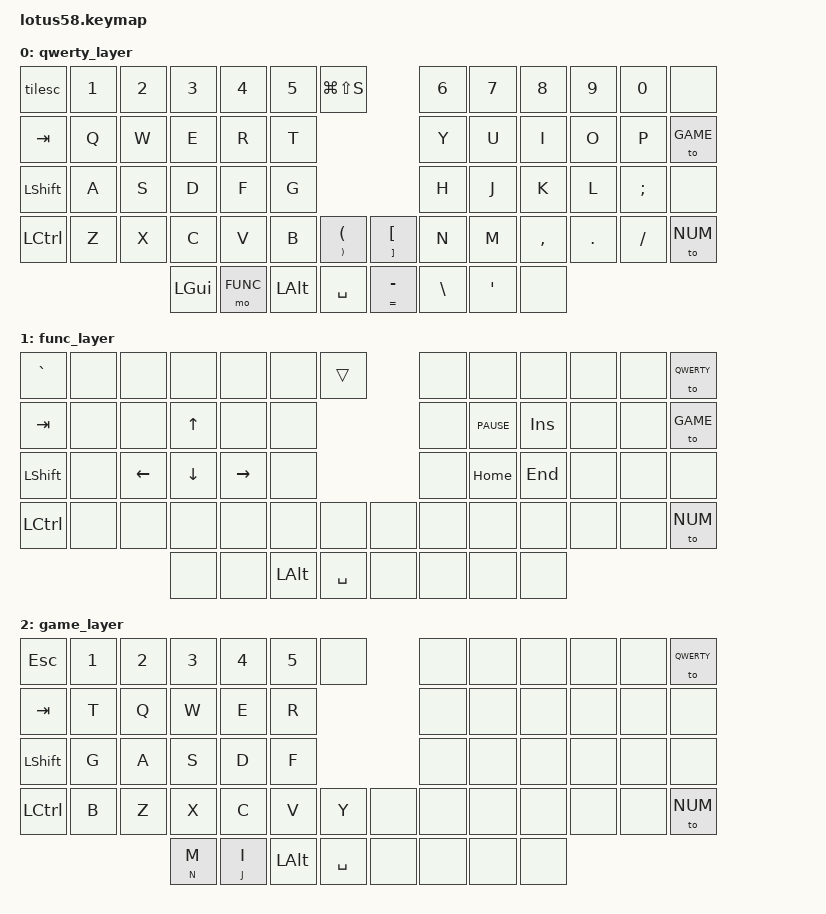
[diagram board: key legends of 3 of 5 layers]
/*
 * Copyright (c) 2020 The ZMK Contributors
 *
 * SPDX-License-Identifier: MIT
 */

#include <behaviors.dtsi>
#include <dt-bindings/zmk/keys.h>
#include <dt-bindings/zmk/bt.h>
#include <dt-bindings/zmk/ext_power.h>

#define ___ &none
#define QWERTY 0
#define FUNC 1
#define GAME 2
#define NUM 3
#define PAUSE PAUSE_BREAK
#define MULTIPLY KP_MULTIPLY

&kscan0 {
    debounce-period = <20>;
};

&sk {
	release-after-ms = <200>;
};

&mt {
	tapping-term-ms = <100>;
};

/ {
	behaviors {
		tilesc: mod_morph_tilde_escape {
			compatible = "zmk,behavior-mod-morph";
			label = "TILDE_ESCAPE";
			#binding-cells = <0>;
			bindings = <&kp ESC>, <&kp TILDE>;
			mods = <(MOD_LSFT)>;
		};

		tlt: behavior_toLayer_tap {
            compatible = "zmk,behavior-hold-tap";
            label = "sticky_tap";
            #binding-cells = <2>;
            flavor = "tap-preferred";
            tapping-term-ms = <200>;
            bindings = <&to>, <&kp>;
        };

		tglt: behavior_togLayer_tap {
            compatible = "zmk,behavior-hold-tap";
            label = "toggle_tap";
            #binding-cells = <2>;
            flavor = "tap-preferred";
            tapping-term-ms = <200>;
            bindings = <&tog>, <&kp>;
        };

	};

	combos {
		compatible = "zmk,combos";

        combo_f1 {
            timeout-ms = <25>;
            key-positions = <0 1>;
            bindings = <&kp F1>;
        };

		combo_f2 {
            timeout-ms = <25>;
            key-positions = <1 2>;
            bindings = <&kp F2>;
        };

		combo_f3 {
            timeout-ms = <25>;
            key-positions = <2 3>;
            bindings = <&kp F3>;
        };

		combo_f4 {
            timeout-ms = <25>;
            key-positions = <3 4>;
            bindings = <&kp F4>;
        };

		combo_f5 {
            timeout-ms = <25>;
            key-positions = <4 5>;
            bindings = <&kp F5>;
        };

		combo_f6 {
            timeout-ms = <25>;
            key-positions = <7 8>;
            bindings = <&kp F6>;
        };

		combo_f7 {
            timeout-ms = <25>;
            key-positions = <8 9>;
            bindings = <&kp F7>;
        };

		combo_f8 {
            timeout-ms = <25>;
            key-positions = <9 10>;
            bindings = <&kp F8>;
        };

		combo_f9 {
            timeout-ms = <25>;
            key-positions = <10 11>;
            bindings = <&kp F9>;
        };

		combo_f10 {
            timeout-ms = <25>;
            key-positions = <11 12>;
            bindings = <&kp F10>;
        };

		combo_f11 {
            timeout-ms = <25>;
            key-positions = <0 2>;
            bindings = <&kp F11>;
        };

		combo_f12 {
            timeout-ms = <25>;
            key-positions = <0 3>;
            bindings = <&kp F12>;
        };

        combo_ret {
            timeout-ms = <50>;
            key-positions = <43 54>;
            bindings = <&kp RET>;
        };
        
        combo_bspc {
            timeout-ms = <25>;
            key-positions = <16 17>;
            bindings = <&kp BSPC>;
        };

        combo_del {
            timeout-ms = <25>;
            key-positions = <15 16 17>;
            bindings = <&kp DEL>;
        };
	};

	keymap {
		compatible = "zmk,keymap";

		qwerty_layer {
			bindings = <
/*    ╭─────────────┬─────────────┬─────────────┬─────────────┬─────────────┬─────────────┬─────────────╮   ╭─────────────┬─────────────┬─────────────┬─────────────┬─────────────┬─────────────┬─────────────╮ */
       &tilesc       &kp N1        &kp N2        &kp N3        &kp N4        &kp N5        &kp LG(LS(S))                   &kp N6        &kp N7        &kp N8		 &kp N9  	   &kp N0   	 ___
/*    ├─────────────┼─────────────┼─────────────┼─────────────┼─────────────┼─────────────┼─────────────╯   ╰─────────────┼─────────────┼─────────────┼─────────────┼─────────────┼─────────────┼─────────────┤ */
       &kp TAB	     &kp Q  	   &kp W  	     &kp E    	   &kp R		 &kp T                     					   &kp Y         &kp U		   &kp I   	     &kp O   	   &kp P    	 &to GAME
/*    ├─────────────┼─────────────┼─────────────┼─────────────┼─────────────┼─────────────┤                               ├─────────────┼─────────────┼─────────────┼─────────────┼─────────────┼─────────────┤ */
       &kp LSHFT	 &kp A  	   &kp S 	     &kp D    	   &kp F    	 &kp G                      				   &kp H	     &kp J		   &kp K   	     &kp L   	   &kp SEMI 	 ___
/*    ├─────────────┼─────────────┼─────────────┼─────────────┼─────────────┼─────────────┼─────────────╮   ╭─────────────┼─────────────┼─────────────┼─────────────┼─────────────┼─────────────┼─────────────┤ */
       &kp LCTRL 	 &kp Z  	   &kp X  	     &kp C    	   &kp V		 &kp B		   &mt RPAR LPAR     &mt RBKT LBKT &kp N	     &kp M		   &kp COMMA 	 &kp DOT 	   &kp FSLH 	 &to NUM
/*    ╰─────────────┴─────────────┴─────────────┼─────────────┼─────────────┼─────────────┼─────────────┤   ├─────────────┼─────────────┼─────────────┴─────────────┴─────────────┴─────────────┴─────────────╯ */
                                                 &kp LGUI 	   &mo FUNC 	 &kp LALT  	   &kp SPACE  		 &mt EQUAL MINUS &kp BSLH     &kp SQT    	___
/*                                              ╰─────────────┴─────────────┴─────────────┴─────────────╯   ╰─────────────┴─────────────┴─────────────┴─────────────╯                                           */
			>;

			sensor-bindings = <&inc_dec_kp PG_UP PG_DN>;
		};

		func_layer {
			bindings = <
/*    ╭─────────────┬─────────────┬─────────────┬─────────────┬─────────────┬─────────────┬─────────────╮   ╭─────────────┬─────────────┬─────────────┬─────────────┬─────────────┬─────────────┬─────────────╮ */
       &kp GRAVE     ___	       ___		     ___		   ___           ___		   &trans		                   ___           ___           ___           ___           ___           &to QWERTY
/*    ├─────────────┼─────────────┼─────────────┼─────────────┼─────────────┼─────────────┼─────────────╯   ╰─────────────┼─────────────┼─────────────┼─────────────┼─────────────┼─────────────┼─────────────┤ */
       &kp TAB	     ___           ___		     &kp UP		   ___	         ___							               ___           &kp PAUSE     &kp INS	     ___           ___	         &to GAME
/*    ├─────────────┼─────────────┼─────────────┼─────────────┼─────────────┼─────────────┤                               ├─────────────┼─────────────┼─────────────┼─────────────┼─────────────┼─────────────┤ */
       &kp LSHFT	 ___           &kp LEFT	     &kp DOWN	   &kp RIGHT     ___							               ___      	 &kp HOME      &kp END	     ___	       ___	         ___
/*    ├─────────────┼─────────────┼─────────────┼─────────────┼─────────────┼─────────────┼─────────────╮   ╭─────────────┼─────────────┼─────────────┼─────────────┼─────────────┼─────────────┼─────────────┤ */
       &kp LCTRL     ___	       ___		     ___           ___           ___    	   ___		         ___           ___           ___   	       ___           ___           ___       	 &to NUM
/*    ╰─────────────┴─────────────┴─────────────┼─────────────┼─────────────┼─────────────┼─────────────┤   ├─────────────┼─────────────┼─────────────┴─────────────┴─────────────┴─────────────┴─────────────╯ */
                                                 ___           ___	         &kp LALT      &kp SPACE	     ___	       ___	         ___	       ___
/*                                              ╰─────────────┴─────────────┴─────────────┴─────────────╯   ╰─────────────┴─────────────┴─────────────┴─────────────╯                                           */
			>;

			sensor-bindings = <&inc_dec_kp C_VOL_UP C_VOL_DN>;
		};

		game_layer {
			bindings = <
/*    ╭─────────────┬─────────────┬─────────────┬─────────────┬─────────────┬─────────────┬─────────────╮   ╭─────────────┬─────────────┬─────────────┬─────────────┬─────────────┬─────────────┬─────────────╮ */
       &kp ESC		 &kp N1	       &kp N2	     &kp N3        &kp N4        &kp N5   	   ___        	                   ___           ___           ___           ___           ___           &to QWERTY
/*    ├─────────────┼─────────────┼─────────────┼─────────────┼─────────────┼─────────────┼─────────────╯   ╰─────────────┼─────────────┼─────────────┼─────────────┼─────────────┼─────────────┼─────────────┤ */
       &kp TAB		 &kp T         &kp Q 	     &kp W         &kp E         &kp R                 	                       ___           ___           ___           ___           ___           ___
/*    ├─────────────┼─────────────┼─────────────┼─────────────┼─────────────┼─────────────┤                               ├─────────────┼─────────────┼─────────────┼─────────────┼─────────────┼─────────────┤ */
       &kp LSHFT	 &kp G	       &kp A  	     &kp S         &kp D         &kp F                 	                       ___           ___           ___           ___           ___           ___
/*    ├─────────────┼─────────────┼─────────────┼─────────────┼─────────────┼─────────────┼─────────────╮   ╭─────────────┼─────────────┼─────────────┼─────────────┼─────────────┼─────────────┼─────────────┤ */
       &kp LCTRL 	 &kp B	       &kp Z  	     &kp X         &kp C         &kp V    	   &kp Y   	         ___           ___           ___           ___           ___           ___           &to NUM
/*    ╰─────────────┴─────────────┴─────────────┼─────────────┼─────────────┼─────────────┼─────────────┤   ├─────────────┼─────────────┼─────────────┴─────────────┴─────────────┴─────────────┴─────────────╯ */
                     		                     &mt N M       &mt J I       &kp LALT      &kp SPACE	     ___           ___           ___           ___
/*                                              ╰─────────────┴─────────────┴─────────────┴─────────────╯   ╰─────────────┴─────────────┴─────────────┴─────────────╯                                           */
			>;

			sensor-bindings = <&inc_dec_kp PG_UP PG_DN>;
		};

		number_layer {
			bindings = <
/*    ╭─────────────┬─────────────┬─────────────┬─────────────┬─────────────┬─────────────┬─────────────╮   ╭─────────────┬─────────────┬─────────────┬─────────────┬─────────────┬─────────────┬─────────────╮ */
       ___           ___           ___           ___           ___           ___           ___               ___           ___           &kp KP_NLCK   &kp KP_SLASH  &kp MULTIPLY  &kp KP_MINUS  &to QWERTY
/*    ├─────────────┼─────────────┼─────────────┼─────────────┼─────────────┼─────────────┼─────────────╯   ╰─────────────┼─────────────┼─────────────┼─────────────┼─────────────┼─────────────┼─────────────┤ */
       ___           ___           ___           ___           ___           ___                                           ___           &kp KP_N7     &kp KP_N8     &kp KP_N9     &kp KP_PLUS   &to GAME
/*    ├─────────────┼─────────────┼─────────────┼─────────────┼─────────────┼─────────────┤                               ├─────────────┼─────────────┼─────────────┼─────────────┼─────────────┼─────────────┤ */
       ___           ___           ___           ___           ___           ___                                           ___           &kp KP_N4     &kp KP_N5     &kp KP_N6     ___           ___
/*    ├─────────────┼─────────────┼─────────────┼─────────────┼─────────────┼─────────────┼─────────────╮   ╭─────────────┼─────────────┼─────────────┼─────────────┼─────────────┼─────────────┼─────────────┤ */
       ___           ___           ___           ___           ___           ___           ___               ___           ___           &kp KP_N1     &kp KP_N2     &kp KP_N3     ___           ___
/*    ╰─────────────┴─────────────┴─────────────┼─────────────┼─────────────┼─────────────┼─────────────┤   ├─────────────┼─────────────┼─────────────┴─────────────┴─────────────┴─────────────┴─────────────╯ */
                     		                     ___           ___           ___           ___               &kp KP_ENTER  &kp N0        &kp DOT       ___
/*                                              ╰─────────────┴─────────────┴─────────────┴─────────────╯   ╰─────────────┴─────────────┴─────────────┴─────────────╯                                           */
			>;

			sensor-bindings = <&inc_dec_kp C_VOL_UP C_VOL_DN>;
		};

		blank_layer {
			bindings = <
/*    ╭─────────────┬─────────────┬─────────────┬─────────────┬─────────────┬─────────────┬─────────────╮   ╭─────────────┬─────────────┬─────────────┬─────────────┬─────────────┬─────────────┬─────────────╮ */
       ___           ___           ___           ___           ___           ___           ___               ___           ___           ___           ___           ___           ___           &to QWERTY
/*    ├─────────────┼─────────────┼─────────────┼─────────────┼─────────────┼─────────────┼─────────────╯   ╰─────────────┼─────────────┼─────────────┼─────────────┼─────────────┼─────────────┼─────────────┤ */
       ___           &kp Q         ___           ___           ___           ___                                           ___           ___           ___           ___           ___           ___
/*    ├─────────────┼─────────────┼─────────────┼─────────────┼─────────────┼─────────────┤                               ├─────────────┼─────────────┼─────────────┼─────────────┼─────────────┼─────────────┤ */
       ___           ___           ___           ___           ___           ___                                           ___           ___           ___           ___           ___           ___
/*    ├─────────────┼─────────────┼─────────────┼─────────────┼─────────────┼─────────────┼─────────────╮   ╭─────────────┼─────────────┼─────────────┼─────────────┼─────────────┼─────────────┼─────────────┤ */
       ___           ___           ___           ___           ___           ___           ___               ___           ___           ___           ___           ___           ___           ___
/*    ╰─────────────┴─────────────┴─────────────┼─────────────┼─────────────┼─────────────┼─────────────┤   ├─────────────┼─────────────┼─────────────┴─────────────┴─────────────┴─────────────┴─────────────╯ */
                     		                     ___           ___           ___           ___               ___           ___           ___           ___
/*                                              ╰─────────────┴─────────────┴─────────────┴─────────────╯   ╰─────────────┴─────────────┴─────────────┴─────────────╯                                           */
			>;

			sensor-bindings = <&inc_dec_kp C_VOL_UP C_VOL_DN>;
		};
	};
};
